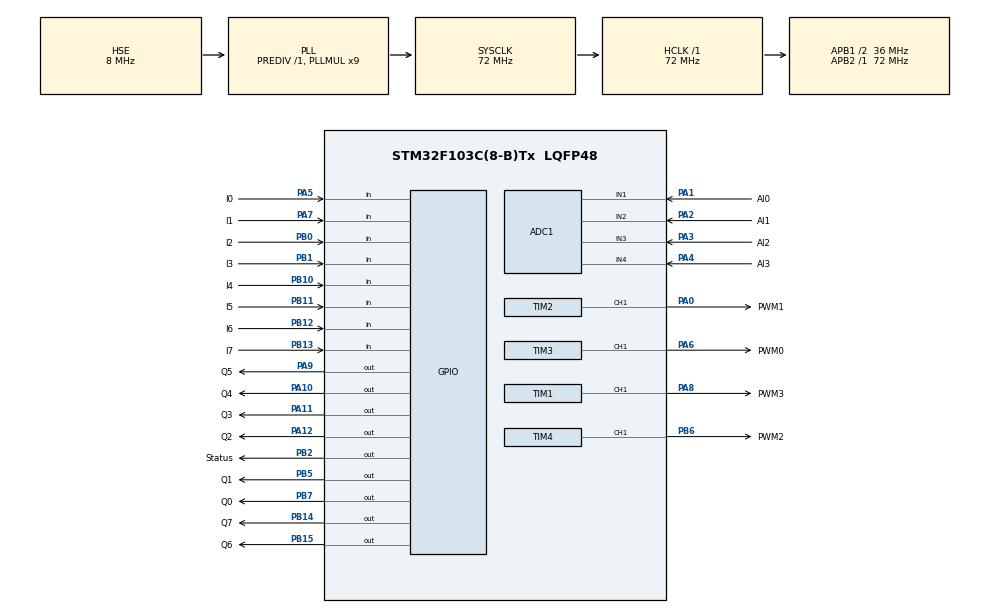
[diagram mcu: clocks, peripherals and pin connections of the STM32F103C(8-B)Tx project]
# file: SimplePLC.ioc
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ADC1.Channel-0\#ChannelRegularConversion=ADC_CHANNEL_1
ADC1.NbrOfConversionFlag=1
ADC1.Rank-0\#ChannelRegularConversion=1
ADC1.SamplingTime-0\#ChannelRegularConversion=ADC_SAMPLETIME_1CYCLE_5
ADC1.master=1
Mcu.Family=STM32F1
Mcu.Name=STM32F103C(8-B)Tx
Mcu.Package=LQFP48
NVIC.PriorityGroup=NVIC_PRIORITYGROUP_4
PA0-WKUP.GPIO_Label=PWM1
PA0-WKUP.Signal=S_TIM2_CH1_ETR
PA1.GPIO_Label=AI0
PA1.Signal=ADCx_IN1
PA10.GPIO_Label=Q4
PA10.Signal=GPIO_Output
PA11.GPIO_Label=Q3
PA11.Signal=GPIO_Output
PA12.GPIO_Label=Q2
PA12.Signal=GPIO_Output
PA13.Mode=Serial_Wire
PA13.Signal=SYS_JTMS-SWDIO
PA14.Mode=Serial_Wire
PA14.Signal=SYS_JTCK-SWCLK
PA2.GPIO_Label=AI1
PA2.Signal=ADCx_IN2
PA3.GPIO_Label=AI2
PA3.Signal=ADCx_IN3
PA4.GPIO_Label=AI3
PA4.Signal=ADCx_IN4
PA5.GPIO_Label=I0
PA5.GPIO_PuPd=GPIO_PULLDOWN
PA5.Signal=GPIO_Input
PA6.GPIO_Label=PWM0
PA6.Signal=S_TIM3_CH1
PA7.GPIO_Label=I1
PA7.GPIO_PuPd=GPIO_PULLDOWN
PA7.Signal=GPIO_Input
PA8.GPIO_Label=PWM3
PA8.Signal=S_TIM1_CH1
PA9.GPIO_Label=Q5
PA9.Signal=GPIO_Output
PB0.GPIO_Label=I2
PB0.GPIO_PuPd=GPIO_PULLDOWN
PB0.Signal=GPIO_Input
PB1.GPIO_Label=I3
PB1.GPIO_PuPd=GPIO_PULLDOWN
PB1.Signal=GPIO_Input
PB10.GPIO_Label=I4
PB10.GPIO_PuPd=GPIO_PULLDOWN
PB10.Signal=GPIO_Input
PB11.GPIO_Label=I5
PB11.GPIO_PuPd=GPIO_PULLDOWN
PB11.Signal=GPIO_Input
PB12.GPIO_Label=I6
PB12.GPIO_PuPd=GPIO_PULLDOWN
PB12.Signal=GPIO_Input
PB13.GPIO_Label=I7
PB13.GPIO_PuPd=GPIO_PULLDOWN
PB13.Signal=GPIO_Input
PB14.GPIO_Label=Q7
PB14.Signal=GPIO_Output
PB15.GPIO_Label=Q6
PB15.Signal=GPIO_Output
PB2.GPIO_Label=Status
PB2.Signal=GPIO_Output
PB5.GPIO_Label=Q1
PB5.Signal=GPIO_Output
PB6.GPIO_Label=PWM2
PB6.Signal=S_TIM4_CH1
PB7.GPIO_Label=Q0
PB7.Signal=GPIO_Output
PD0-OSC_IN.Mode=HSE-External-Oscillator
PD0-OSC_IN.Signal=RCC_OSC_IN
PD1-OSC_OUT.Mode=HSE-External-Oscillator
PD1-OSC_OUT.Signal=RCC_OSC_OUT
ProjectManager.HeapSize=0x200
ProjectManager.StackSize=0x400
ProjectManager.TargetToolchain=Other Toolchains (GPDSC)
RCC.ADCPresc=RCC_ADCPCLK2_DIV6
RCC.AHBFreq_Value=72000000
RCC.APB1CLKDivider=RCC_HCLK_DIV2
RCC.APB1Freq_Value=36000000
RCC.APB1TimFreq_Value=72000000
RCC.APB2Freq_Value=72000000
RCC.APB2TimFreq_Value=72000000
RCC.HCLKFreq_Value=72000000
RCC.PLLMUL=RCC_PLL_MUL9
RCC.PLLSourceVirtual=RCC_PLLSOURCE_HSE
RCC.SYSCLKFreq_VALUE=72000000
RCC.SYSCLKSource=RCC_SYSCLKSOURCE_PLLCLK
RCC.USBFreq_Value=72000000
SH.ADCx_IN1.0=ADC1_IN1,IN1
SH.ADCx_IN2.0=ADC1_IN2,IN2
SH.ADCx_IN3.0=ADC1_IN3,IN3
SH.ADCx_IN4.0=ADC1_IN4,IN4
SH.S_TIM1_CH1.0=TIM1_CH1,PWM Generation1 CH1
SH.S_TIM2_CH1_ETR.0=TIM2_CH1,PWM Generation1 CH1
SH.S_TIM3_CH1.0=TIM3_CH1,PWM Generation1 CH1
SH.S_TIM4_CH1.0=TIM4_CH1,PWM Generation1 CH1
TIM1.Channel-PWM\ Generation1\ CH1=TIM_CHANNEL_1
TIM2.Channel-PWM\ Generation1\ CH1=TIM_CHANNEL_1
TIM3.Channel-PWM\ Generation1\ CH1=TIM_CHANNEL_1
TIM4.Channel-PWM\ Generation1\ CH1=TIM_CHANNEL_1
VP_TIM1_VS_ClockSourceINT.Mode=Internal
VP_TIM2_VS_ClockSourceINT.Mode=Internal
VP_TIM3_VS_ClockSourceINT.Mode=Internal
VP_TIM4_VS_ClockSourceINT.Mode=Internal
board=custom

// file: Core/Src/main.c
/* USER CODE BEGIN Header */
/**
  ******************************************************************************
  * @file           : main.c
  * @brief          : Main program body
  ******************************************************************************
  * @attention
  *
  * <h2><center>&copy; Copyright (c) 2020 STMicroelectronics.
  * All rights reserved.</center></h2>
  *
  * This software component is licensed by ST under BSD 3-Clause license,
  * the "License"; You may not use this file except in compliance with the
  * License. You may obtain a copy of the License at:
  *                        opensource.org/licenses/BSD-3-Clause
  *
  ******************************************************************************
  */
/* USER CODE END Header */
#include "main.h"

/* USER CODE BEGIN Includes */
#include "SimplePLCv1.h"
#include "program.h"
/* USER CODE END Includes */

ADC_HandleTypeDef hadc1;

TIM_HandleTypeDef htim1;
TIM_HandleTypeDef htim2;
TIM_HandleTypeDef htim3;
TIM_HandleTypeDef htim4;

void SystemClock_Config(void);
static void MX_GPIO_Init(void);
static void MX_ADC1_Init(void);
static void MX_TIM1_Init(void);
static void MX_TIM2_Init(void);
static void MX_TIM3_Init(void);
static void MX_TIM4_Init(void);

/* USER CODE BEGIN 0 */
uint32_t counter = 0;
/* USER CODE END 0 */

int main(void)
{

  /* MCU Configuration--------------------------------------------------------*/

  /* Reset of all peripherals, Initializes the Flash interface and the Systick. */
  HAL_Init();

  /* Configure the system clock */
  SystemClock_Config();

  /* Initialize all configured peripherals */
  MX_GPIO_Init();
  MX_ADC1_Init();
  MX_TIM1_Init();
  MX_TIM2_Init();
  MX_TIM3_Init();
  MX_TIM4_Init();
  /* USER CODE BEGIN 2 */
    SimplePLCv1_Initialize();
  /* USER CODE END 2 */

  /* Infinite loop */
  /* USER CODE BEGIN WHILE */
    InitCycle();
  while (1)
  {
    /* USER CODE END WHILE */

    /* USER CODE BEGIN 3 */
    MainCycle();
  }
  /* USER CODE END 3 */
}

void SystemClock_Config(void)
{
  RCC_OscInitTypeDef RCC_OscInitStruct = {0};
  RCC_ClkInitTypeDef RCC_ClkInitStruct = {0};
  RCC_PeriphCLKInitTypeDef PeriphClkInit = {0};

  /** Initializes the RCC Oscillators according to the specified parameters
  * in the RCC_OscInitTypeDef structure.
  */
  RCC_OscInitStruct.OscillatorType = RCC_OSCILLATORTYPE_HSE;
  RCC_OscInitStruct.HSEState = RCC_HSE_ON;
  RCC_OscInitStruct.HSEPredivValue = RCC_HSE_PREDIV_DIV1;
  RCC_OscInitStruct.HSIState = RCC_HSI_ON;
  RCC_OscInitStruct.PLL.PLLState = RCC_PLL_ON;
  RCC_OscInitStruct.PLL.PLLSource = RCC_PLLSOURCE_HSE;
  RCC_OscInitStruct.PLL.PLLMUL = RCC_PLL_MUL9;
  if (HAL_RCC_OscConfig(&RCC_OscInitStruct) != HAL_OK)
  {
    Error_Handler();
  }
  /** Initializes the CPU, AHB and APB buses clocks
  */
  RCC_ClkInitStruct.ClockType = RCC_CLOCKTYPE_HCLK|RCC_CLOCKTYPE_SYSCLK
                              |RCC_CLOCKTYPE_PCLK1|RCC_CLOCKTYPE_PCLK2;
  RCC_ClkInitStruct.SYSCLKSource = RCC_SYSCLKSOURCE_PLLCLK;
  RCC_ClkInitStruct.AHBCLKDivider = RCC_SYSCLK_DIV1;
  RCC_ClkInitStruct.APB1CLKDivider = RCC_HCLK_DIV2;
  RCC_ClkInitStruct.APB2CLKDivider = RCC_HCLK_DIV1;

  if (HAL_RCC_ClockConfig(&RCC_ClkInitStruct, FLASH_LATENCY_2) != HAL_OK)
  {
    Error_Handler();
  }
  PeriphClkInit.PeriphClockSelection = RCC_PERIPHCLK_ADC;
  PeriphClkInit.AdcClockSelection = RCC_ADCPCLK2_DIV6;
  if (HAL_RCCEx_PeriphCLKConfig(&PeriphClkInit) != HAL_OK)
  {
    Error_Handler();
  }
}

static void MX_ADC1_Init(void)
{

  ADC_ChannelConfTypeDef sConfig = {0};

  /** Common config
  */
  hadc1.Instance = ADC1;
  hadc1.Init.ScanConvMode = ADC_SCAN_DISABLE;
  hadc1.Init.ContinuousConvMode = DISABLE;
  hadc1.Init.DiscontinuousConvMode = DISABLE;
  hadc1.Init.ExternalTrigConv = ADC_SOFTWARE_START;
  hadc1.Init.DataAlign = ADC_DATAALIGN_RIGHT;
  hadc1.Init.NbrOfConversion = 1;
  if (HAL_ADC_Init(&hadc1) != HAL_OK)
  {
    Error_Handler();
  }
  /** Configure Regular Channel
  */
  sConfig.Channel = ADC_CHANNEL_1;
  sConfig.Rank = ADC_REGULAR_RANK_1;
  sConfig.SamplingTime = ADC_SAMPLETIME_1CYCLE_5;
  if (HAL_ADC_ConfigChannel(&hadc1, &sConfig) != HAL_OK)
  {
    Error_Handler();
  }

}

static void MX_TIM1_Init(void)
{

  TIM_ClockConfigTypeDef sClockSourceConfig = {0};
  TIM_MasterConfigTypeDef sMasterConfig = {0};
  TIM_OC_InitTypeDef sConfigOC = {0};
  TIM_BreakDeadTimeConfigTypeDef sBreakDeadTimeConfig = {0};

  htim1.Instance = TIM1;
  htim1.Init.Prescaler = 0;
  htim1.Init.CounterMode = TIM_COUNTERMODE_UP;
  htim1.Init.Period = 65535;
  htim1.Init.ClockDivision = TIM_CLOCKDIVISION_DIV1;
  htim1.Init.RepetitionCounter = 0;
  htim1.Init.AutoReloadPreload = TIM_AUTORELOAD_PRELOAD_DISABLE;
  if (HAL_TIM_Base_Init(&htim1) != HAL_OK)
  {
    Error_Handler();
  }
  sClockSourceConfig.ClockSource = TIM_CLOCKSOURCE_INTERNAL;
  if (HAL_TIM_ConfigClockSource(&htim1, &sClockSourceConfig) != HAL_OK)
  {
    Error_Handler();
  }
  if (HAL_TIM_PWM_Init(&htim1) != HAL_OK)
  {
    Error_Handler();
  }
  sMasterConfig.MasterOutputTrigger = TIM_TRGO_RESET;
  sMasterConfig.MasterSlaveMode = TIM_MASTERSLAVEMODE_DISABLE;
  if (HAL_TIMEx_MasterConfigSynchronization(&htim1, &sMasterConfig) != HAL_OK)
  {
    Error_Handler();
  }
  sConfigOC.OCMode = TIM_OCMODE_PWM1;
  sConfigOC.Pulse = 0;
  sConfigOC.OCPolarity = TIM_OCPOLARITY_HIGH;
  sConfigOC.OCNPolarity = TIM_OCNPOLARITY_HIGH;
  sConfigOC.OCFastMode = TIM_OCFAST_DISABLE;
  sConfigOC.OCIdleState = TIM_OCIDLESTATE_RESET;
  sConfigOC.OCNIdleState = TIM_OCNIDLESTATE_RESET;
  if (HAL_TIM_PWM_ConfigChannel(&htim1, &sConfigOC, TIM_CHANNEL_1) != HAL_OK)
  {
    Error_Handler();
  }
  sBreakDeadTimeConfig.OffStateRunMode = TIM_OSSR_DISABLE;
  sBreakDeadTimeConfig.OffStateIDLEMode = TIM_OSSI_DISABLE;
  sBreakDeadTimeConfig.LockLevel = TIM_LOCKLEVEL_OFF;
  sBreakDeadTimeConfig.DeadTime = 0;
  sBreakDeadTimeConfig.BreakState = TIM_BREAK_DISABLE;
  sBreakDeadTimeConfig.BreakPolarity = TIM_BREAKPOLARITY_HIGH;
  sBreakDeadTimeConfig.AutomaticOutput = TIM_AUTOMATICOUTPUT_DISABLE;
  if (HAL_TIMEx_ConfigBreakDeadTime(&htim1, &sBreakDeadTimeConfig) != HAL_OK)
  {
    Error_Handler();
  }
  HAL_TIM_MspPostInit(&htim1);

}

static void MX_TIM2_Init(void)
{

  TIM_ClockConfigTypeDef sClockSourceConfig = {0};
  TIM_MasterConfigTypeDef sMasterConfig = {0};
  TIM_OC_InitTypeDef sConfigOC = {0};

  htim2.Instance = TIM2;
  htim2.Init.Prescaler = 0;
  htim2.Init.CounterMode = TIM_COUNTERMODE_UP;
  htim2.Init.Period = 65535;
  htim2.Init.ClockDivision = TIM_CLOCKDIVISION_DIV1;
  htim2.Init.AutoReloadPreload = TIM_AUTORELOAD_PRELOAD_DISABLE;
  if (HAL_TIM_Base_Init(&htim2) != HAL_OK)
  {
    Error_Handler();
  }
  sClockSourceConfig.ClockSource = TIM_CLOCKSOURCE_INTERNAL;
  if (HAL_TIM_ConfigClockSource(&htim2, &sClockSourceConfig) != HAL_OK)
  {
    Error_Handler();
  }
  if (HAL_TIM_PWM_Init(&htim2) != HAL_OK)
  {
    Error_Handler();
  }
  sMasterConfig.MasterOutputTrigger = TIM_TRGO_RESET;
  sMasterConfig.MasterSlaveMode = TIM_MASTERSLAVEMODE_DISABLE;
  if (HAL_TIMEx_MasterConfigSynchronization(&htim2, &sMasterConfig) != HAL_OK)
  {
    Error_Handler();
  }
  sConfigOC.OCMode = TIM_OCMODE_PWM1;
  sConfigOC.Pulse = 0;
  sConfigOC.OCPolarity = TIM_OCPOLARITY_HIGH;
  sConfigOC.OCFastMode = TIM_OCFAST_DISABLE;
  if (HAL_TIM_PWM_ConfigChannel(&htim2, &sConfigOC, TIM_CHANNEL_1) != HAL_OK)
  {
    Error_Handler();
  }
  HAL_TIM_MspPostInit(&htim2);

}

static void MX_TIM3_Init(void)
{

  TIM_ClockConfigTypeDef sClockSourceConfig = {0};
  TIM_MasterConfigTypeDef sMasterConfig = {0};
  TIM_OC_InitTypeDef sConfigOC = {0};

  htim3.Instance = TIM3;
  htim3.Init.Prescaler = 0;
  htim3.Init.CounterMode = TIM_COUNTERMODE_UP;
  htim3.Init.Period = 65535;
  htim3.Init.ClockDivision = TIM_CLOCKDIVISION_DIV1;
  htim3.Init.AutoReloadPreload = TIM_AUTORELOAD_PRELOAD_DISABLE;
  if (HAL_TIM_Base_Init(&htim3) != HAL_OK)
  {
    Error_Handler();
  }
  sClockSourceConfig.ClockSource = TIM_CLOCKSOURCE_INTERNAL;
  if (HAL_TIM_ConfigClockSource(&htim3, &sClockSourceConfig) != HAL_OK)
  {
    Error_Handler();
  }
  if (HAL_TIM_PWM_Init(&htim3) != HAL_OK)
  {
    Error_Handler();
  }
  sMasterConfig.MasterOutputTrigger = TIM_TRGO_RESET;
  sMasterConfig.MasterSlaveMode = TIM_MASTERSLAVEMODE_DISABLE;
  if (HAL_TIMEx_MasterConfigSynchronization(&htim3, &sMasterConfig) != HAL_OK)
  {
    Error_Handler();
  }
  sConfigOC.OCMode = TIM_OCMODE_PWM1;
  sConfigOC.Pulse = 0;
  sConfigOC.OCPolarity = TIM_OCPOLARITY_HIGH;
  sConfigOC.OCFastMode = TIM_OCFAST_DISABLE;
  if (HAL_TIM_PWM_ConfigChannel(&htim3, &sConfigOC, TIM_CHANNEL_1) != HAL_OK)
  {
    Error_Handler();
  }
  HAL_TIM_MspPostInit(&htim3);

}

static void MX_TIM4_Init(void)
{

  TIM_ClockConfigTypeDef sClockSourceConfig = {0};
  TIM_MasterConfigTypeDef sMasterConfig = {0};
  TIM_OC_InitTypeDef sConfigOC = {0};

  htim4.Instance = TIM4;
  htim4.Init.Prescaler = 0;
  htim4.Init.CounterMode = TIM_COUNTERMODE_UP;
  htim4.Init.Period = 65535;
  htim4.Init.ClockDivision = TIM_CLOCKDIVISION_DIV1;
  htim4.Init.AutoReloadPreload = TIM_AUTORELOAD_PRELOAD_DISABLE;
  if (HAL_TIM_Base_Init(&htim4) != HAL_OK)
  {
    Error_Handler();
  }
  sClockSourceConfig.ClockSource = TIM_CLOCKSOURCE_INTERNAL;
  if (HAL_TIM_ConfigClockSource(&htim4, &sClockSourceConfig) != HAL_OK)
  {
    Error_Handler();
  }
  if (HAL_TIM_PWM_Init(&htim4) != HAL_OK)
  {
    Error_Handler();
  }
  sMasterConfig.MasterOutputTrigger = TIM_TRGO_RESET;
  sMasterConfig.MasterSlaveMode = TIM_MASTERSLAVEMODE_DISABLE;
  if (HAL_TIMEx_MasterConfigSynchronization(&htim4, &sMasterConfig) != HAL_OK)
  {
    Error_Handler();
  }
  sConfigOC.OCMode = TIM_OCMODE_PWM1;
  sConfigOC.Pulse = 0;
  sConfigOC.OCPolarity = TIM_OCPOLARITY_HIGH;
  sConfigOC.OCFastMode = TIM_OCFAST_DISABLE;
  if (HAL_TIM_PWM_ConfigChannel(&htim4, &sConfigOC, TIM_CHANNEL_1) != HAL_OK)
  {
    Error_Handler();
  }
  HAL_TIM_MspPostInit(&htim4);

}

static void MX_GPIO_Init(void)
{
  GPIO_InitTypeDef GPIO_InitStruct = {0};

  /* GPIO Ports Clock Enable */
  __HAL_RCC_GPIOD_CLK_ENABLE();
  __HAL_RCC_GPIOA_CLK_ENABLE();
  __HAL_RCC_GPIOB_CLK_ENABLE();

  /*Configure GPIO pin Output Level */
  HAL_GPIO_WritePin(GPIOB, Status_Pin|Q7_Pin|Q6_Pin|Q1_Pin
                          |Q0_Pin, GPIO_PIN_RESET);

  /*Configure GPIO pin Output Level */
  HAL_GPIO_WritePin(GPIOA, Q5_Pin|Q4_Pin|Q3_Pin|Q2_Pin, GPIO_PIN_RESET);

  /*Configure GPIO pins : I0_Pin I1_Pin */
  GPIO_InitStruct.Pin = I0_Pin|I1_Pin;
  GPIO_InitStruct.Mode = GPIO_MODE_INPUT;
  GPIO_InitStruct.Pull = GPIO_PULLDOWN;
  HAL_GPIO_Init(GPIOA, &GPIO_InitStruct);

  /*Configure GPIO pins : I2_Pin I3_Pin I4_Pin I5_Pin
                           I6_Pin I7_Pin */
  GPIO_InitStruct.Pin = I2_Pin|I3_Pin|I4_Pin|I5_Pin
                          |I6_Pin|I7_Pin;
  GPIO_InitStruct.Mode = GPIO_MODE_INPUT;
  GPIO_InitStruct.Pull = GPIO_PULLDOWN;
  HAL_GPIO_Init(GPIOB, &GPIO_InitStruct);

  /*Configure GPIO pins : Status_Pin Q7_Pin Q6_Pin Q1_Pin
                           Q0_Pin */
  GPIO_InitStruct.Pin = Status_Pin|Q7_Pin|Q6_Pin|Q1_Pin
                          |Q0_Pin;
  GPIO_InitStruct.Mode = GPIO_MODE_OUTPUT_PP;
  GPIO_InitStruct.Pull = GPIO_NOPULL;
  GPIO_InitStruct.Speed = GPIO_SPEED_FREQ_LOW;
  HAL_GPIO_Init(GPIOB, &GPIO_InitStruct);

  /*Configure GPIO pins : Q5_Pin Q4_Pin Q3_Pin Q2_Pin */
  GPIO_InitStruct.Pin = Q5_Pin|Q4_Pin|Q3_Pin|Q2_Pin;
  GPIO_InitStruct.Mode = GPIO_MODE_OUTPUT_PP;
  GPIO_InitStruct.Pull = GPIO_NOPULL;
  GPIO_InitStruct.Speed = GPIO_SPEED_FREQ_LOW;
  HAL_GPIO_Init(GPIOA, &GPIO_InitStruct);

}

void Error_Handler(void)
{
}

/************************ (C) COPYRIGHT STMicroelectronics *****END OF FILE****/
